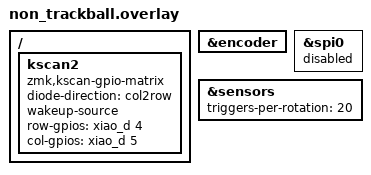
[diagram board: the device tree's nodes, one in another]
/delete-node/ &kscan2;

&encoder {
    status = "okay";
};

&spi0 {
    status = "disabled";
};

/ {
    // 物理ピン
    kscan2: kscan2 {
        compatible = "zmk,kscan-gpio-matrix";
        diode-direction = "col2row";    // カソードが行
        wakeup-source;
        row-gpios
            = <&xiao_d 4 (GPIO_ACTIVE_HIGH | GPIO_PULL_DOWN)>
            ; 

        col-gpios
            = <&xiao_d 5 GPIO_ACTIVE_HIGH>
            ; 
    };
};

&sensors {
    // 2026-07-11: 12だと回転を検出するまでに感覚的にかなり回す必要があったため
    // 20に増やして試す(一般的なロータリーエンコーダーの物理クリック数に近い値)。
    // 実機で感度を確認し、必要ならさらに調整する
    triggers-per-rotation = <20>;
};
